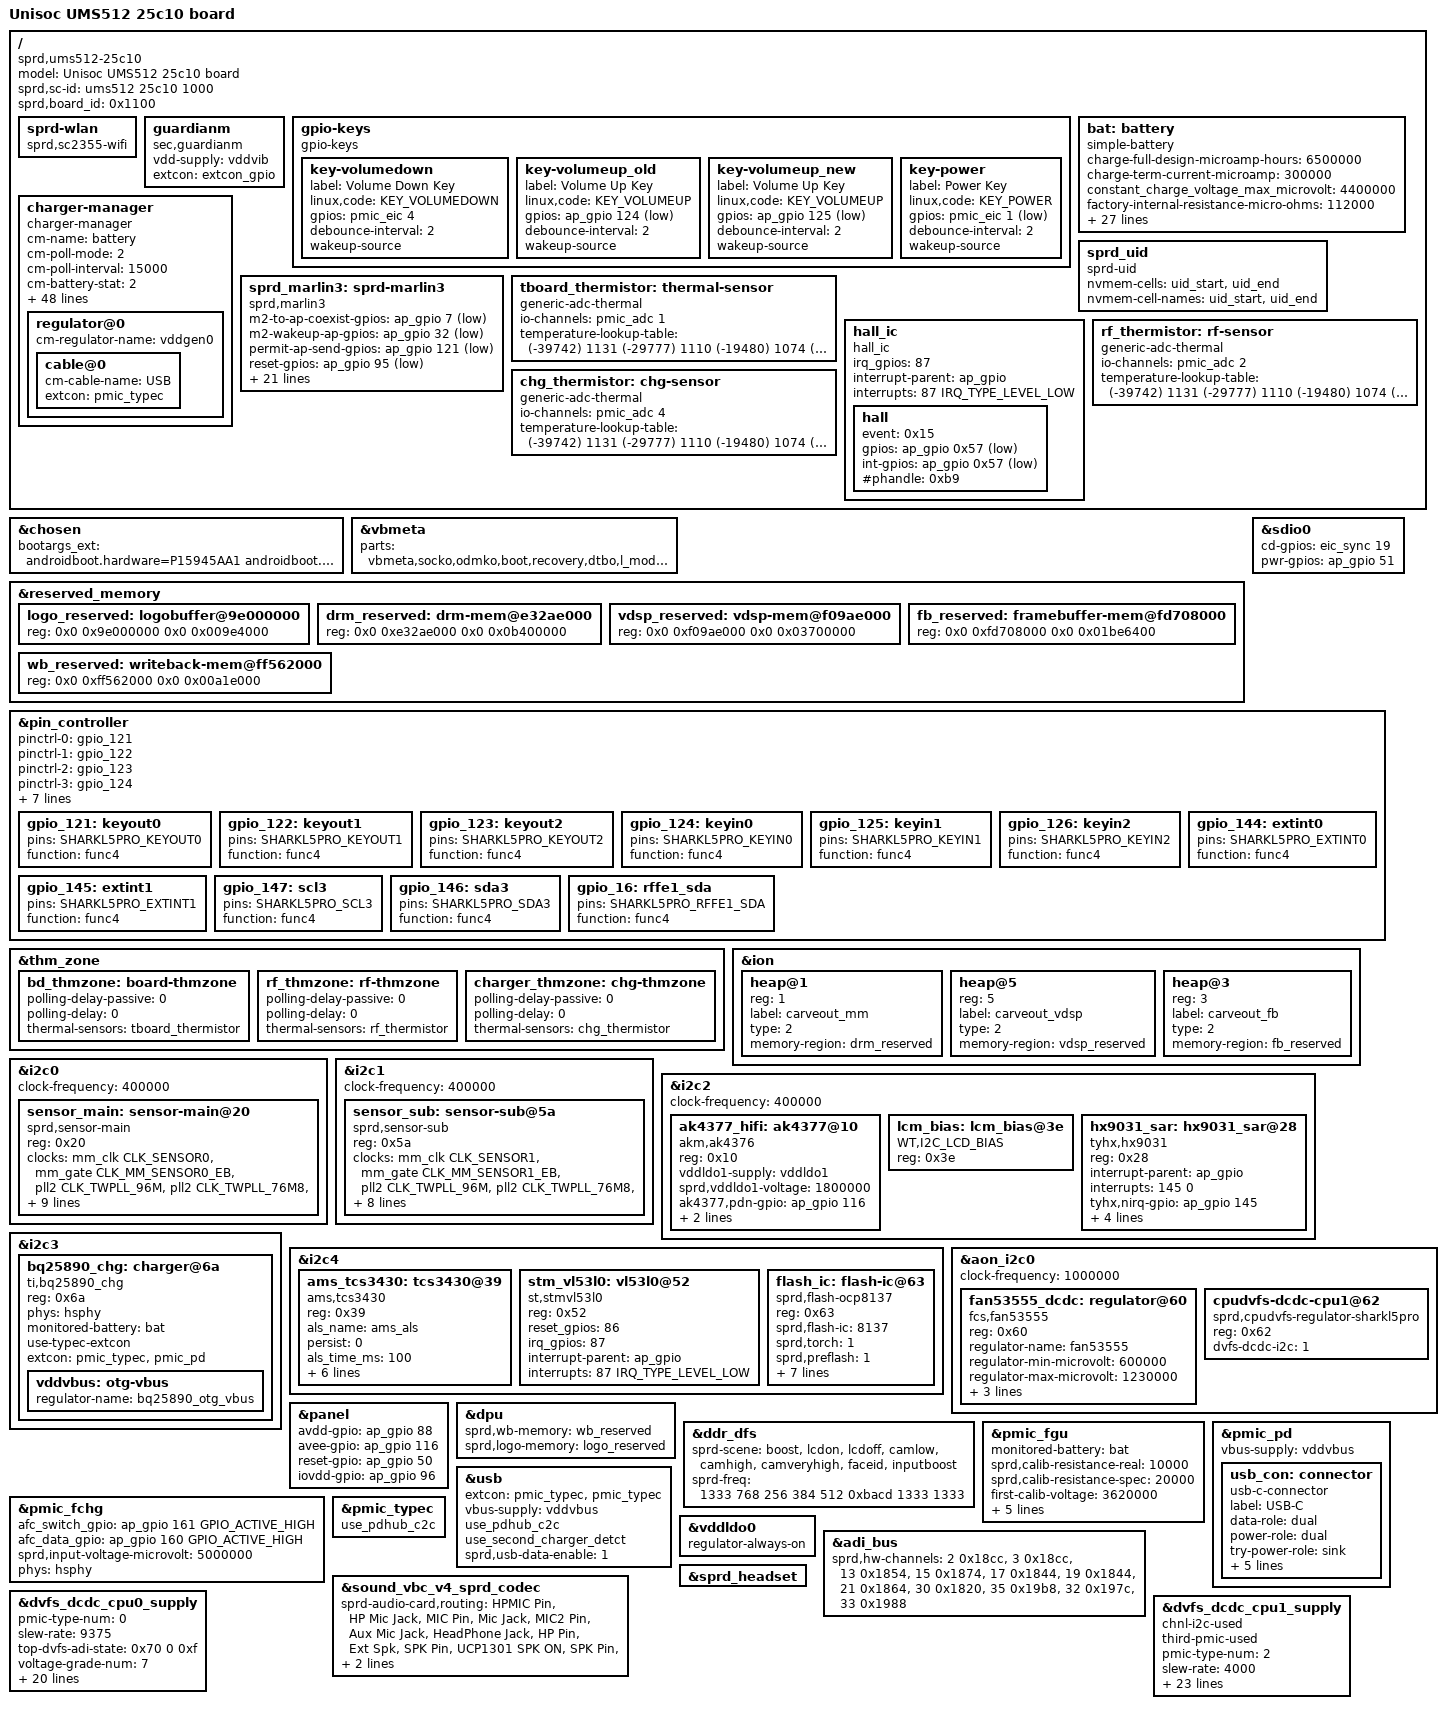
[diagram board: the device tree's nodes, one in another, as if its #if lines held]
/dts-v1/;
/plugin/;

#include <dt-bindings/input/input.h>
#include <dt-bindings/gpio/gpio.h>
#include <dt-bindings/usb/pd.h>
#include <dt-bindings/interrupt-controller/arm-gic.h>
#include <dt-bindings/clock/sprd,sharkl5pro-clk.h>
#include <dt-bindings/mfd/sprd,sc2730-regs.h>
#include <dt-bindings/mfd/sprd,sc2730-mask.h>
#include <dt-bindings/wdv/wdv.h>
//+Bug760817, pengzhenhua1.wt, add, 20220525, lcd bringup
#include "lcd/lcd_nt36523b_lce_panda_video_fhdp.dtsi"
#include "lcd/lcd_hx83102e_lide_al_hsd_video_fhdp.dtsi"
#include "lcd/lcd_hx83102e_txd_al_hsd_video_fhdp.dtsi"
//-Bug760817, pengzhenhua1.wt, add, 20220525, lcd bringup
#include "lcd/lcd_dummy_mipi.dtsi"
//+Bug760817, fangzhihua.wt, add, 20220527, TP bringup
#include "ums512_touch_1200_2000.dtsi"
//-Bug760817, fangzhihua.wt, add, 20220527, TP bringup
#include "ums512-25c10-sec-common.dtsi"
/ {

	model = "Unisoc UMS512 25c10 board";
	compatible = "sprd,ums512-25c10";
	sprd,sc-id = "ums512 25c10 1000";
	sprd,board_id = <0x1100>; //XX00:base board,XX00~XXFF:customize board

	fragment {
		target-path = "/";
		__overlay__ {
			sprd-wlan {
				compatible = "sprd,sc2355-wifi";
			};

            // #+bug 760817,lh.wt,add,2022/05/25,Bring up for boot normal
			guardianm {
				compatible = "sec,guardianm";
				vdd-supply = <&vddvib>;
				extcon = <&extcon_gpio>;
			};
           // #-bug 760817,lh.wt,add,2022/05/25,Bring up for boot normal

			gpio-keys {
				compatible = "gpio-keys";

				key-volumedown {
					label = "Volume Down Key";
					linux,code = <KEY_VOLUMEDOWN>;
					gpios = <&pmic_eic 4 GPIO_ACTIVE_HIGH>;
					debounce-interval = <2>;
					wakeup-source;
				};

				key-volumeup_old {
					label = "Volume Up Key";
					linux,code = <KEY_VOLUMEUP>;
					gpios = <&ap_gpio 124 GPIO_ACTIVE_LOW>;
					debounce-interval = <2>;
					wakeup-source;
				};

				key-volumeup_new {
					label = "Volume Up Key";
					linux,code = <KEY_VOLUMEUP>;
					gpios = <&ap_gpio 125 GPIO_ACTIVE_LOW>;
					debounce-interval = <2>;
					wakeup-source;
				};

				key-power {
					label = "Power Key";
					linux,code = <KEY_POWER>;
					gpios = <&pmic_eic 1 GPIO_ACTIVE_LOW>;
					debounce-interval = <2>;
					wakeup-source;
				};
			};
//+Bug760817, pengzhenhua1.wt, del, 20220525, lcd bringup
/*			pwm_backlight: backlight {
				compatible = "sprd,sharkl5pro-backlight";
				pwms = <&pwms 2 40000>;
				pwm-names = "backlight";
				sprd,max-brightness-level = <880>;
				default-brightness-level = <250>;
				sprd,brightness-scale = <1023>;
				brightness-levels = <
							  0   3   4   5   6   7
					  8   9  10  11  12  13  14  15  16  17
					 18  19  20  21  22  23  24  25  26  27
					 28  29  31  33  35  37  39  41  43  45
					 46  48  50  52  54  56  58  60  62  64
					 66  68  70  72  74  76  78  80  82  84
					 86  88  90  92  94  96  98 100 102 104
					106 108 110 112 114 116 118 120 122 124
					126 128 130 132 134 136 138 140 142 144
					146 148 150 152 154 156 158 160 162 164
					166 169 172 175 178 181 184 187 190 193
					196 199 202 205 208 211 214 217 220 223
					226 229 232 235 238 241 244 247 250 253
					256 259 262 265 268 271 274 277 280 283
					286 290 294 298 302 306 310 314 318 322
					326 330 334 338 342 346 350 354 358 362
					366 370 374 378 382 386 390 394 398 402
					406 410 414 418 422 426 430 434 438 442
					446 451 456 461 466 471 476 481 486 491
					496 501 506 511 516 521 526 531 536 541
					546 551 556 561 566 571 576 581 586 591
					596 601 606 611 616 621 626 631 636 641
					646 652 658 664 670 676 682 688 694 700
					706 712 718 724 730 736 742 748 754 760
					766 772 778 784 790 796 802 808 814 820
					826 832 838 844 850 856 862 868 874 880
				>;
			};*/
//-Bug760817, pengzhenhua1.wt, del, 20220525, lcd bringup
			bat: battery {
				compatible = "simple-battery";
				charge-full-design-microamp-hours = <6500000>;
				charge-term-current-microamp = <300000>;
				constant_charge_voltage_max_microvolt = <4400000>;
				factory-internal-resistance-micro-ohms = <112000>;
				voltage-min-design-microvolt = <3450000>;
				ocv-capacity-celsius = <20>;
				ocv-capacity-table-0 = <4375000 100>, <4314000 95>, <4256000 90>,
							<4198000 85>, <4142000 80>, <4089000 75>,
							<4039000 70>, <3991000 65>, <3950000 60>,
							<3893000 55>, <3855000 50>, <3829000 45>,
							<3808000 40>, <3791000 35>, <3777000 30>,
							<3758000 25>, <3739000 20>, <3715000 15>,
							<3685000 10>, <3669000 5>, <3400000 0>;
//+bug 696970, liyiying.wt, mod, 2022/4/14, update the ntc param
				voltage-temp-table = <1109180 800>, <998134 850>, <888589 900>,
							  <783521 950>, <685075 1000>, <594767 1050>,
							  <513541 1100>, <441675 1150>, <379014 1200>,
							  <324561 1250>, <277923 1300>, <238054 1350>,
							  <204093 1400>, <175179 1450>, <150596 1500>,
							  <129683 1550>, <111939 1600>, <96799 1650>,
							  <83908 1700>, <72935 1750>, <63552 1800>,
							  <55403 1850>, <48338 1900>, <42195 1950>;
//-bug 696970, liyiying.wt, mod, 2022/4/14, update the ntc param
//+bug 696970, liyiying.wt, mod, 2022/4/23, update the battery capacity - temp compensation meter
				capacity-temp-table = <25 100>, <10 85>, <0 80>, <(-5) 65>, <(-10) 45>, <(-20) 30>;
//-bug 696970, liyiying.wt, mod, 2022/4/23, update the battery capacity - temp compensation meter
				resistance-temp-table = <45 77>, <25 100>, <10 546>, <0 769>, <(-10) 892>, <(-20) 923>;
				charge-sdp-current-microamp = <500000 500000>;
				charge-dcp-current-microamp = <2000000 1660000>;
				charge-cdp-current-microamp = <1000000 1000000>;
				charge-unknown-current-microamp = <500000 500000>;
				charge-fchg-current-microamp = <3000000 1670000>;
			};

			charger-manager {
				compatible = "charger-manager";
				cm-name = "battery";
				cm-poll-mode = <2>;
				cm-poll-interval = <15000>;
				cm-battery-stat = <2>;

				cm-fullbatt-vchkdrop-ms = <30000>;
				cm-fullbatt-vchkdrop-volt = <60000>;
				cm-fullbatt-voltage = <4380000>;
				cm-fullbatt-current = <300000>;
				cm-fullbatt-capacity = <100>;

				//cm-multi-charger-adapt-enable;
				cm-chargers = "bq25890_charger";
				cm-fast-chargers = "sc2730_fast_charger";
				cm-fuel-gauge = "sc27xx-fgu";
				cm-power-supplys = "bq25890_charger";


				/* in deci centigrade */
				cm-battery-cold = <200>;
				cm-battery-cold-in-minus;
				cm-battery-hot = <800>;
				cm-battery-temp-diff = <100>;

				/* Allow charging for 36hr */
				cm-charging-max = <129600000>;
				/* recovery charging after stop charging 45min */
				cm-discharging-max = <2700000>;

				/* the interval to feed charger watchdog */
				cm-wdt-interval = <60>;

				/* drop voltage in microVolts to allow shutdown */
				cm-shutdown-voltage = <3400000>;

				/* when 99% of the time is exceeded, it will be forced to 100% */
				cm-tickle-time-out = <1500>;

				/* how much time to allow capacity change */
//ExtB[P220419-05969], liyiying.wt, mod, 2022/4/22, the uisoc drop down speed is to fast
				cm-one-cap-time = <40>;
				cm-thermal-zone = "board-thmzone";
				/* when the safe charging voltage is exceeded, stop charging */
				cm-charge-voltage-max = <6500000>;
				/* drop voltage in microVolts to restart charging */
				cm-charge-voltage-drop = <700000>;
				
				cm-fast-charge-voltage-max = <10500000>;
				cm-fast-charge-voltage-drop = <700000>;
				
				cm-dcp-jeita-temp-table = <1010 1030 0 4200000>, <1150 1180 1000000 4200000>,
					<1450 1420 2000000 4400000>, <1550 1530 2000000 4100000>;
				cm-sdp-jeita-temp-table = <1010 1030 0 4200000>, <1150 1180 500000 4200000>,
					<1450 1420 500000 4400000>, <1550 1530 500000 4100000>;
				cm-cdp-jeita-temp-table = <1010 1030 0 4200000>, <1150 1180 1000000 4200000>,
					<1450 1420 1000000 4400000>, <1550 1530 1000000 4100000>;
				cm-unknown-jeita-temp-table = <1010 1030 0 4200000>, <1150 1180 500000 4200000>,
					<1450 1420 500000 4400000>, <1550 1530 500000 4100000>;
				cm-fchg-jeita-temp-table = <1010 1030 0 4200000>, <1150 1180 1000000 4200000>,
					<1450 1420 3000000 4400000>, <1550 1530 3000000 4100000>;
					
				monitored-battery = <&bat>;

				cm-cap-remap-table =<0 1 3>, <1 2 3>, <2 3 2>, <98 99 2>, <99 100 3>;

				regulator@0 {
					cm-regulator-name = "vddgen0";
					cable@0 {
						cm-cable-name = "USB";
						extcon = <&pmic_typec>;
					};
				};
			};

			sprd_uid {
				compatible = "sprd-uid";
				nvmem-cells = <&uid_start>, <&uid_end>;
				nvmem-cell-names = "uid_start", "uid_end";
			};

			sprd_marlin3: sprd-marlin3 {
				compatible = "sprd,marlin3";
				m2-to-ap-coexist-gpios = <&ap_gpio 7 GPIO_ACTIVE_LOW>;
				m2-wakeup-ap-gpios = <&ap_gpio 32 GPIO_ACTIVE_LOW>;
				permit-ap-send-gpios = <&ap_gpio 121 GPIO_ACTIVE_LOW>;
				reset-gpios = <&ap_gpio 95 GPIO_ACTIVE_LOW>;
				enable-gpios = <&ap_gpio 16 GPIO_ACTIVE_LOW>;
				m2-to-ap-irq-gpios = <&ap_gpio 94 GPIO_ACTIVE_LOW>;
				xtal-26m-clk-type = "TSX";
                                avdd12-supply = <&vddwcn>;
				avdd33-supply = <&vddwifipa>;
				dcxo18-supply = <&vddsim2>;

				clock-names = "clk_32k","source","enable";
				clocks = <&aon_clk CLK_AUX0>,
					 <&ext_32k>,
					 <&aonapb_gate CLK_AUX0_EB>;

				sdhci-name = <&sdio1>;
				sprd,btwf-file-name = "/dev/block/platform/soc/soc:ap-apb/71400000.sdio/by-name/wcnmodem";
				sprd,gnss-file-name = "/dev/block/platform/soc/soc:ap-apb/71400000.sdio/by-name/gnssmodem";
				adma-tx;
				adma-rx;
				/*
				 * bound parameter:
				 * [0]:addr offset, [1]:mask, [2]:unboundval, [3]:boundval
				 */
				avdd12-parent-bound-chip = <REG_ANA_SLP_DCDC_PD_CTRL MASK_ANA_SLP_DCDCGEN1_PD_EN 0x0 MASK_ANA_SLP_DCDCGEN1_PD_EN>;
				avdd12-bound-wbreq = <REG_ANA_LDO_XTL_EN10 MASK_ANA_LDO_VDDWCN_EXT_XTL3_EN 0x0 MASK_ANA_LDO_VDDWCN_EXT_XTL3_EN>;
				avdd33-bound-wbreq = <REG_ANA_LDO_XTL_EN11 MASK_ANA_LDO_VDDWIFIPA_EXT_XTL3_EN 0x0 MASK_ANA_LDO_VDDWIFIPA_EXT_XTL3_EN>;
			};

			tboard_thermistor:thermal-sensor {
				compatible = "generic-adc-thermal";
				#thermal-sensor-cells = <0>;
				io-channels = <&pmic_adc 1>;
				io-channel-names = "sensor-channel";
				temperature-lookup-table = <    (-39742) 1131
								(-29777) 1110
								(-19480) 1074
								(-4679) 983
								10110 838
								24805 654
								44922 413
								54903 316
								64895 238
								74884 178
								84883 133
								94883 100
								104880 75
								114889 57
								124872 43 >;
			};
			hall_ic:hall_ic {
			compatible = "hall_ic";
			irq_gpios = <87>;
			interrupt-parent = <&ap_gpio>;
			interrupts = <87 IRQ_TYPE_LEVEL_LOW>;
			status = "okay";

				hall {
					event = <0x15>;
					gpios = <&ap_gpio 0x57 0x1>;
					int-gpios = <&ap_gpio 0x57 0x1>;
					#phandle = <0xb9>;
				};

			};

			//+Bug750447,luojianhao.wt,add,20220615,add thermal NTC
			rf_thermistor:rf-sensor {
				compatible = "generic-adc-thermal";
				#thermal-sensor-cells = <0>;
				io-channels = <&pmic_adc 2>;
				io-channel-names = "sensor-channel";
				temperature-lookup-table = <	(-39742) 1131
								(-29777) 1110
								(-19480) 1074
								(-4679) 983
								10110 838
								24805 654
								44922 413
								54903 316
								64895 238
								74884 178
								84883 133
								94883 100
								104880 75
								114889 57
								124872 43 >;
			};
			chg_thermistor:chg-sensor {
				compatible = "generic-adc-thermal";
				#thermal-sensor-cells = <0>;
				io-channels = <&pmic_adc 4>;
				io-channel-names = "sensor-channel";
				temperature-lookup-table = <	(-39742) 1131
								(-29777) 1110
								(-19480) 1074
								(-4679) 983
								10110 838
								24805 654
								44922 413
								54903 316
								64895 238
								74884 178
								84883 133
								94883 100
								104880 75
								114889 57
								124872 43 >;
			};
			//-Bug750447,luojianhao.wt,add,20220615,add thermal NTC
		};
	};
};

&chosen {
	bootargs_ext = "androidboot.hardware=P15945AA1 androidboot.dtbo_idx=0";
};

&vbmeta {
	parts = "vbmeta,socko,odmko,boot,recovery,dtbo,l_modem,pm_sys,l_ldsp,l_gdsp,l_agdsp";
};

&reserved_memory {

	logo_reserved: logobuffer@9e000000{
		reg = <0x0 0x9e000000 0x0 0x009e4000>;
	};

#ifdef BSP_KERNEL_CONFIG_WIDEVINE_L1
	drm_reserved: drm-mem@e32ae000 {
		reg = <0x0 0xe32ae000 0x0 0x0b400000>;
	};
#endif

	/*fd_reserved: faceid-mem@efaae000 {
		reg = <0x0 0xefaae000 0x0 0x00500000>;
	};*/

	vdsp_reserved: vdsp-mem@f09ae000 {
		reg = <0x0 0xf09ae000 0x0 0x03700000>;
	};
/*
	gpu_reserved: gpu-mem@fb8ae000 {
		reg = <0x0 0xfb8ae000 0x0 0x01e5a000>;
	};
*/

	fb_reserved: framebuffer-mem@fd708000 {
		reg = <0x0 0xfd708000 0x0 0x01be6400>;
	};

	wb_reserved: writeback-mem@ff562000 {
		reg = <0x0 0xff562000 0x0 0x00a1e000>;
	};

};

&sdio0 {
	cd-gpios = <&eic_sync 19 GPIO_ACTIVE_HIGH>;
	pwr-gpios = <&ap_gpio 51 0>;
};

&pin_controller {
	pinctrl-names =
	/* keyout0 ~ keyout2 */
	"gpio_121", "gpio_122", "gpio_123",
	/* keyin0 ~ keyin2 */
	"gpio_124", "gpio_125", "gpio_126",
	/* extint0, extint1, scl3, sda3, sda */
	"gpio_144", "gpio_145", "gpio_146", "gpio_147", "gpio_16";

	pinctrl-0 = <&gpio_121>;
	pinctrl-1 = <&gpio_122>;
	pinctrl-2 = <&gpio_123>;
	pinctrl-3 = <&gpio_124>;
	pinctrl-4 = <&gpio_125>;
	pinctrl-5 = <&gpio_126>;
	pinctrl-6 = <&gpio_144>;
	pinctrl-7 = <&gpio_145>;
	pinctrl-8 = <&gpio_146>;
	pinctrl-9 = <&gpio_147>;
	pinctrl-10 = <&gpio_16>;

	gpio_121: keyout0 {
		pins = "SHARKL5PRO_KEYOUT0";
		function = "func4";
	};

	gpio_122: keyout1 {
		pins = "SHARKL5PRO_KEYOUT1";
		function = "func4";
	};

	gpio_123: keyout2 {
		pins = "SHARKL5PRO_KEYOUT2";
		function = "func4";
	};

	gpio_124: keyin0 {
		pins = "SHARKL5PRO_KEYIN0";
		function = "func4";
	};

	gpio_125: keyin1 {
		pins = "SHARKL5PRO_KEYIN1";
		function = "func4";
	};

	gpio_126: keyin2 {
		pins = "SHARKL5PRO_KEYIN2";
		function = "func4";
	};

	gpio_144: extint0 {
		pins = "SHARKL5PRO_EXTINT0";
		function = "func4";
	};

	gpio_145: extint1 {
		pins = "SHARKL5PRO_EXTINT1";
		function = "func4";
	};

	gpio_147: scl3 {
		pins = "SHARKL5PRO_SCL3";
		function = "func4";
	};

	gpio_146: sda3 {
		pins = "SHARKL5PRO_SDA3";
		function = "func4";
	};

	gpio_16: rffe1_sda {
		pins = "SHARKL5PRO_RFFE1_SDA";
		function = "func4";
	};
};

&thm_zone {
	bd_thmzone: board-thmzone {
		polling-delay-passive = <0>;
		polling-delay = <0>;
		thermal-sensors = <&tboard_thermistor>;
	};
	//+Bug750447,luojianhao.wt,add,20220615,add thermal NTC
	rf_thmzone: rf-thmzone {
		polling-delay-passive = <0>;
		polling-delay = <0>;
		thermal-sensors = <&rf_thermistor>;
	};
	charger_thmzone: chg-thmzone {
		polling-delay-passive = <0>;
		polling-delay = <0>;
		thermal-sensors = <&chg_thermistor>;
	};
	//-Bug750447,luojianhao.wt,add,20220615,add thermal NTC
};

&ion {
#ifdef BSP_KERNEL_CONFIG_WIDEVINE_L1
	heap@1 {
		reg = <1>;
		label = "carveout_mm";
		type = <2>;
		memory-region = <&drm_reserved>;
	};
#endif

	/*heap@4 {
		reg = <4>;
		label = "carveout_fd";
		type = <2>;
		memory-region = <&fd_reserved>;
	};*/

	heap@5 {
		reg = <5>;
		label = "carveout_vdsp";
		type = <2>;
		memory-region = <&vdsp_reserved>;
	};
};
//+bug760817,lihuan1wingtech.com,mod,20220526,add camera bring up code
&i2c0 {
	#address-cells = <1>;
	#size-cells = <0>;

	status = "okay";
	clock-frequency = <400000>;

	sensor_main: sensor-main@20 {
		compatible = "sprd,sensor-main";
		reg = <0x20>;
		clock-names = "clk_src","sensor_eb",
			"clk_96m","clk_76m8",
			"clk_48m","clk_26m";
		clocks = <&mm_clk CLK_SENSOR0>,<&mm_gate CLK_MM_SENSOR0_EB>,
				<&pll2 CLK_TWPLL_96M>,<&pll2 CLK_TWPLL_76M8>,
				<&pll2 CLK_TWPLL_48M>,<&ext_26m>;
		vddio-supply = <&vddcamio>;
		vddcama-supply = <&vddcama1>;
		vddcamd-supply = <&vddcamd0>;
		vddcammot-supply = <&vddcammot>;
		reset-gpios = <&ap_gpio 45 0>;
		power-down-gpios = <&ap_gpio 46 0>;
		sprd,phyid = <0>;
		csi = <&csi0>;
	};


};

&i2c1 {
	#address-cells = <1>;
	#size-cells = <0>;

	status = "okay";
	clock-frequency = <400000>;

	sensor_sub: sensor-sub@5a {
		compatible = "sprd,sensor-sub";
		reg = <0x5a>;
		clock-names = "clk_src","sensor_eb",
			"clk_96m","clk_76m8",
			"clk_48m","clk_26m";
		clocks = <&mm_clk CLK_SENSOR1>,<&mm_gate CLK_MM_SENSOR1_EB>,
				<&pll2 CLK_TWPLL_96M>,<&pll2 CLK_TWPLL_76M8>,
				<&pll2 CLK_TWPLL_48M>,<&ext_26m>;
		vddio-supply = <&vddcamio>;
		vddcama-supply = <&vddcama1>;
		vddcamd-supply = <&vddcamd1>;
		//vddcammot-supply = <&vddcammot>;
		reset-gpios = <&ap_gpio 44 0>;
		power-down-gpios = <&ap_gpio 47 0>;
		sprd,phyid = <2>;
		csi = <&csi1>;
	};

/*
	sensor_main2: sensor-main2@20 {
		compatible = "sprd,sensor-main2";
		reg = <0x20>;
		clock-names = "clk_src","sensor_eb",
			"clk_96m","clk_76m8",
			"clk_48m","clk_26m";
		clocks = <&mm_clk CLK_SENSOR1>,<&mm_gate CLK_MM_SENSOR1_EB>,
				<&pll2 CLK_TWPLL_96M>,<&pll2 CLK_TWPLL_76M8>,
				<&pll2 CLK_TWPLL_48M>,<&ext_26m>;
		vddio-supply = <&vddcamio>;
		vddcama-supply = <&vddcama1>;
		vddcamd-supply = <&vddcamd1>;
		vddcammot-supply = <&vddcammot>;
		avdd-gpios = <&ap_gpio 33 0>;
		mot-gpios = <&ap_gpio 88 0>;
		reset-gpios = <&ap_gpio 45 0>;
		power-down-gpios = <&ap_gpio 47 0>;
		mipi-switch-en-gpios = <&ap_gpio 55 0>;
		mipi-switch-mode-gpios = <&ap_gpio 8 0>;
		sprd,phyid = <1>;
		csi = <&csi1>;
	};

	sensor_sub2: sensor-sub2@6e {
		compatible = "sprd,sensor-sub2";
		reg = <0x6e>;
		clock-names = "clk_src","sensor_eb",
			"clk_96m","clk_76m8",
			"clk_48m","clk_26m";
		clocks = <&mm_clk CLK_SENSOR1>,<&mm_gate CLK_MM_SENSOR1_EB>,
			<&pll2 CLK_TWPLL_96M>,<&pll2 CLK_TWPLL_76M8>,
			<&pll2 CLK_TWPLL_48M>,<&ext_26m>;
		vddio-supply = <&vddcamio>;
		vddcama-supply = <&vddcama1>;
		vddcamd-supply = <&vddcamd1>;
		vddcammot-supply = <&vddcammot>;
		mot-gpios = <&ap_gpio 88 0>;
		reset-gpios = <&ap_gpio 41 0>;
		power-down-gpios = <&ap_gpio 40 0>;
		sprd,phyid = <2>;
		csi = <&csi2>;
	};

	sensor_main3: sensor-main3@6c {
		compatible = "sprd,sensor-main3";
		reg = <0x6c>;
		clock-names = "clk_src","sensor_eb",
			"clk_96m","clk_76m8",
			"clk_48m","clk_26m";
		clocks = <&mm_clk CLK_SENSOR1>,<&mm_gate CLK_MM_SENSOR1_EB>,
				<&pll2 CLK_TWPLL_96M>,<&pll2 CLK_TWPLL_76M8>,
				<&pll2 CLK_TWPLL_48M>,<&ext_26m>;
		vddio-supply = <&vddcamio>;
		vddcama-supply = <&vddcama1>;
		vddcamd-supply = <&vddcamd1>;
		vddcammot-supply = <&vddcammot>;
		mot-gpios = <&ap_gpio 88 0>;
		reset-gpios = <&ap_gpio 41 0>;
		power-down-gpios = <&ap_gpio 40 0>;
		sprd,phyid = <2>;
		csi = <&csi2>;
	};
*/
//-bug760817,lihuan1wingtech.com,mod,20220526,add camera bring up code
};

&i2c2 {
	status = "okay";
	clock-frequency = <400000>;

	ak4377_hifi: ak4377@10 {
		compatible = "akm,ak4376";
		reg = <0x10>;
		#sound-dai-cells = <1>;
		vddldo1-supply = <&vddldo1>;
		sprd,vddldo1-voltage = <1800000>;
		ak4377,pdn-gpio = <&ap_gpio 116 GPIO_ACTIVE_HIGH>;

		clock-names = "clk_48M", "source", "enable";
		clocks = <&aon_clk CLK_AUX1>,
			 <&pll2 CLK_TWPLL_19M2>,
			 <&aonapb_gate CLK_AUX1_EB>;
	};
//+Bug760817, pengzhenhua1.wt, add, 20220525, lcd bringup
	lcm_bias: lcm_bias@3e {
		compatible = "WT,I2C_LCD_BIAS";
		reg = <0x3e>;
	};
//-Bug760817, pengzhenhua1.wt, add, 20220525, lcd bringup

	hx9031_sar: hx9031_sar@28 {
		compatible = "tyhx,hx9031";
		reg = <0x28>;
		interrupt-parent = <&ap_gpio>;
		interrupts = <145 0>;
		tyhx,nirq-gpio = <&ap_gpio 145 0>;
		grip-sensor = < 0 >;
		grip-sensor-sub = < 1 >;
		grip-sensor-wifi = < 2 >;
		tyhx,channel-flag = <0x07>;
		status = "okay";
	};		
};

&i2c3 {
	status = "okay";
	bq25890_chg: charger@6a {
		compatible = "ti,bq25890_chg";
		reg = <0x6a>;
		phys = <&hsphy>;
		monitored-battery = <&bat>;
		use-typec-extcon;
		extcon = <&pmic_typec>, <&pmic_pd>;
		vddvbus:otg-vbus {
			regulator-name = "bq25890_otg_vbus";
		};
	};
};

&i2c4 {
	status = "okay";

	/*bq25890_chg: ti_charger@6a {
		compatible = "ti,bq25890_chg";
		reg = <0x6a>;
		phys = <&hsphy>;
		monitored-battery = <&bat>;
		extcon = <&pmic_typec>, <&pmic_pd>;
		pd-extcon-enable;
		use-typec-extcon;
		irq-gpio = <&ap_gpio 156 GPIO_ACTIVE_LOW>;
		bq25890_otg_vbus: bq25890_otg_vbus {
			regulator-name = "bq25890_otg_vbus";
		};
	};*/

	ams_tcs3430: tcs3430@39 {
		compatible = "ams,tcs3430";
		reg = <0x39>;
		als_name = "ams_als";
		persist = <0>;
		als_time_ms = <100>;
		als_gain = <64>;
		int_config = <0>;
		als_can_wake = <1>;
		irq_gpios = <112>;
		interrupt-parent = <&ap_gpio>;
		interrupts = <112 IRQ_TYPE_LEVEL_LOW>;
	};

	stm_vl53l0: vl53l0@52 {
		compatible = "st,stmvl53l0";
		reg = <0x52>;
		reset_gpios = <86>;
		irq_gpios = <87>;
		interrupt-parent = <&ap_gpio>;
		interrupts = <87 IRQ_TYPE_LEVEL_LOW>;
	};

	flash_ic: flash-ic@63 {
		compatible = "sprd,flash-ocp8137";
		reg = <0x63>;
		sprd,flash-ic = <8137>;
		sprd,torch = <1>;
		sprd,preflash = <1>;
		sprd,highlight = <1>;
		sprd,torch-level = <128>;
		sprd,preflash-level = <128>;
		sprd,highlight-level = <128>;
		sprd,lvfm-enable = <1>;
		flash-chip-en-gpios = <&ap_gpio 136 0>;
		flash-en-gpios = <&ap_gpio 137 0>;
	};

};

&aon_i2c0 {
	status = "okay";
	clock-frequency = <1000000>;

	fan53555_dcdc: regulator@60 {
		compatible = "fcs,fan53555";
		reg = <0x60>;
		regulator-name = "fan53555";
		regulator-min-microvolt = <600000>;
		regulator-max-microvolt = <1230000>;
		regulator-ramp-delay = <64000>;
		regulator-always-on;
		fcs,suspend-voltage-selector = <1>;
	};

	/* A virtual i2c device */
	cpudvfs-dcdc-cpu1@62{
		compatible = "sprd,cpudvfs-regulator-sharkl5pro";
		reg = <0x62>;
		dvfs-dcdc-i2c = <1>;
	};
};
//+Bug760817, fangzhihua.wt, mod, 20220527, TP bringup
/*
&spi2 {
	status = "okay";
	cs-gpios = <0>;

	himax_touch@0 {
		compatible = "himax,hxcommon";
		reg = <0>;
		status = "okay";
		spi-max-frequency = <10000000>;
		interrupt-parent = <&ap_gpio>;
		interrupts = <144 0x2004>;
		himax,panel-sense-nums = <18 32>;
		himax,panel-coords = <0 1200 0 1920>;
		himax,display-coords = <0 1200 0 1920>;
		himax,panel-max-points = <10>;
		himax,int-is-edge = <1>;
		himax,irq-gpio = <&ap_gpio 144 GPIO_ACTIVE_HIGH>;
		himax,rst-gpio = <&ap_gpio 145 GPIO_ACTIVE_HIGH>;
		report_type = <1>;
	};
};
*/
//-Bug760817, fangzhihua.wt, add, 20220527, TP bringup
/*
&vddvib {
	regulator-always-on;
};*/
//+Bug760817, pengzhenhua1.wt, modify, 20220525, lcd bringup
&panel {
	avdd-gpio = <&ap_gpio 88 GPIO_ACTIVE_HIGH>;
	avee-gpio = <&ap_gpio 116 GPIO_ACTIVE_HIGH>;
	reset-gpio = <&ap_gpio 50 GPIO_ACTIVE_HIGH>;
	iovdd-gpio = <&ap_gpio 96 GPIO_ACTIVE_HIGH>;	//Bug760817, pengzhenhua1.wt, add, 20220718, lcd bringup
};
//-Bug760817, pengzhenhua1.wt, modify, 20220525, lcd bringup
&dpu {
	sprd,wb-memory = <&wb_reserved>;
	sprd,logo-memory = <&logo_reserved>;
};

&ddr_dfs {
	sprd-scene = "boost", "lcdon", "lcdoff", "camlow",
		"camhigh", "camveryhigh", "faceid", "inputboost";
	sprd-freq = <1333 768 256 384 512 0xbacd 1333 1333>;
};

&pmic_fgu {
	monitored-battery = <&bat>;
	sprd,calib-resistance-real = <10000>;
	sprd,calib-resistance-spec = <20000>;
//ExtB[P220707-05744], liyiying.wt, mod, 2022/08/06, the uisoc drop down speed is to fast
	first-calib-voltage = <3620000>;
	first-calib-capacity = <40>;
	fgu-capacity-track;
	fullbatt-track-end-vol = <4345>;
	fullbatt-track-end-cur = <130>;
	phys = <&hsphy>;
};
&pmic_fchg {
	afc_switch_gpio = <&ap_gpio 161 GPIO_ACTIVE_HIGH>;
	afc_data_gpio = <&ap_gpio 160 GPIO_ACTIVE_HIGH>;
	sprd,input-voltage-microvolt = <5000000>;
	phys = <&hsphy>;
};
 
&pmic_pd {
	status = "okay";
	vbus-supply = <&vddvbus>;
	usb_con: connector {
		compatible = "usb-c-connector";
		label = "USB-C";
		data-role = "dual";
		power-role = "dual";
		try-power-role = "sink";
		source-pdos = <PDO_FIXED(5000, 400, PDO_FIXED_USB_COMM)>;
		sink-pdos = <PDO_FIXED(5000, 2000, PDO_FIXED_USB_COMM)>;
		op-sink-microwatt = <10000000>;
	};
};

&usb {
	extcon = <&pmic_typec>, <&pmic_typec>;
	vbus-supply = <&vddvbus>;
	use_pdhub_c2c;
	use_second_charger_detct;
	sprd,usb-data-enable = <1>;
};

&pmic_typec {
	use_pdhub_c2c;
};

&vddldo0 {
	regulator-always-on;
};

&adi_bus {
	sprd,hw-channels = <2 0x18cc>, <3 0x18cc>, <13 0x1854>, <15 0x1874>,
			 <17 0x1844>,<19 0x1844>, <21 0x1864>, <30 0x1820>,
			 <35 0x19b8>, <32 0x197c>, <33 0x1988>;
};

&sprd_headset {
	status = "okay";
};

&sound_vbc_v4_sprd_codec {
	status = "okay";
	sprd-audio-card,routing =
		"HPMIC Pin", "HP Mic Jack",
		"MIC Pin", "Mic Jack",
		"MIC2 Pin", "Aux Mic Jack",
		"HeadPhone Jack", "HP Pin",
		"Ext Spk", "SPK Pin",
		"UCP1301 SPK ON", "SPK Pin",
		"Ext Spk", "UCP1301 SPK",
		"DMIC Pin", "DMic Jack",
		"DMIC1 Pin", "DMic1 Jack",
		"Ext Ear", "EAR Pin";

	/* 35: ucp1301 normal ap01 */
	/*
	sprd-audio-card,dai-link@53 {
		ignore-suspend = <1>;
		link-name = "BE_NORMAL_AP01_UCPSPK";
		stream-name = "BE_ST_NORMAL_AP01_UCPSPK";
		no-pcm = <1>;
		dpcm-playback = <1>;
		be-id = <0>;
		dai-format = "i2s";
		plat {
			sound-dai = <&sprd_route_pcm>;
		};
		cpu {
			sound-dai = <&vbc_v4 31>;
		};
		codec {
			sound-dai = <&ucp1301_spk 0>;
		};
	};
	*/

	/*
	 * node 54 and node 55 (index 36 and 37) are reserved for
	 * "ucp1301-spk2" and "ucp1301-rcv"
	 * nodes from 56 to 67 (index from 38 to 49) are used by HIFI
	 */
};
&dvfs_dcdc_cpu0_supply {
	pmic-type-num = <0>;
	slew-rate = <9375>; /* 9375uV/us */
	top-dvfs-adi-state = <0x70 0 0xf>;
	voltage-grade-num = <7>;
	voltage-grade = <0 0xf0 0xf4 0 0x1ff>,
		<1 0xf0 0xf4 9 0x1ff>,
		<2 0x100 0xf4 18 0x1ff>,
		<3 0x110 0xf8 0 0x1ff>,
		<4 0x120 0xf8 9 0x1ff>,
		<5 0x130 0xf8 18 0x1ff>,
		<6 0x140 0xfc 0 0x1ff>;
	voltage-up-delay = <50 0x58 0 0xffff 0x600>,
		<100 0x58 16 0xffff 0xa00>,
		<150 0x54 0 0xffff 0xf00>,
		<200 0x54 16 0xffff 0x1400>,
		<250 0x50 0 0xffff 0x1900>,
		<300 0x50 16 0xffff 0x1e00>,
		<350 0x110 0 0xffff 0x2300>;
	voltage-down-delay = <50 0x64 0 0xffff 0x600>,
		<100 0x64 16 0xffff 0xa00>,
		<150 0x60 0 0xffff 0xf00>,
		<200 0x60 16 0xffff 0x1400>,
		<250 0x5c 0 0xffff 0x1900>,
		<300 0x5c 16 0xffff 0x1e00>,
		<350 0x114 0 0xffff 0x2300>;
	tuning-latency-us = <0>;
	chnl-in-i2c = <0>;
};

&dvfs_dcdc_cpu1_supply {
	chnl-i2c-used;
	third-pmic-used;
	pmic-type-num = <2>;
	slew-rate = <4000>; /* 4000uV/us */
	supply-type-sel = <0x120 0 1>;
	top-dvfs-i2c-state = <0x9c 4 0xf>;
	voltage-grade-num = <6>;
	voltage-grade = <0 0x0f 0x12c 0 0x3f>,
		<1 0x14 0x12c 7 0x3f>,
		<2 0x19 0x12c 14 0x3f>,
		<3 0x1e 0x12c 21 0x3f>,
		<4 0x23 0x130 0 0x3f>,
		<5 0x28 0x130 7 0x3f>;
	voltage-up-delay = <50 0x84 0 0xffff 0x1600>,
		<100 0x84 16 0xffff 0x1a00>,
		<150 0x80 0 0xffff 0x1f00>,
		<200 0x80 16 0xffff 0x2400>,
		<250 0x7c 0 0xffff 0x2900>,
		<300 0x7c 16 0xffff 0x2e00>,
		<350 0x118 0 0xffff 0x3300>;
	voltage-down-delay = <50 0x90 0 0xffff 0x600>,
		<100 0x90 16 0xffff 0xa00>,
		<150 0x8c 0 0xffff 0xf00>,
		<200 0x8c 16 0xffff 0x1400>,
		<250 0x88 0 0xffff 0x1900>,
		<300 0x88 16 0xffff 0x1e00>,
		<350 0x11c 0 0xffff 0x2300>;
	tuning-latency-us = <0>;
	chnl-in-i2c = <1>;
};

&ion {
	heap@3 {
		reg = <3>;
		label = "carveout_fb";
		type = <2>;
		memory-region = <&fb_reserved>;
	};
};
